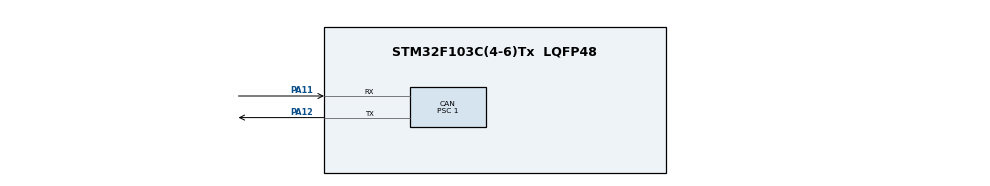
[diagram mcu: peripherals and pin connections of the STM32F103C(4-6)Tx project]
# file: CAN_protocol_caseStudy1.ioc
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CAN.BS1=CAN_BS1_6TQ
CAN.CalculateTimeBit=1000
CAN.CalculateTimeQuantum=125.0
CAN.Mode=CAN_MODE_LOOPBACK
CAN.Prescaler=1
Mcu.Family=STM32F1
Mcu.Name=STM32F103C(4-6)Tx
Mcu.Package=LQFP48
NVIC.PriorityGroup=NVIC_PRIORITYGROUP_4
PA11.Mode=Master
PA11.Signal=CAN_RX
PA12.Mode=Master
PA12.Signal=CAN_TX
ProjectManager.HeapSize=0x200
ProjectManager.StackSize=0x400
ProjectManager.TargetToolchain=STM32CubeIDE
RCC.APB1Freq_Value=8000000
RCC.APB2Freq_Value=8000000
VP_SYS_VS_ND.Mode=No_Debug
board=custom

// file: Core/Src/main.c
/* USER CODE BEGIN Header */
/**
 ******************************************************************************
 * @file           : main.c
 * @brief          : Main program body
 ******************************************************************************
 * @attention
 *
 * <h2><center>&copy; Copyright (c) 2023 STMicroelectronics.
 * All rights reserved.</center></h2>
 *
 * This software component is licensed by ST under BSD 3-Clause license,
 * the "License"; You may not use this file except in compliance with the
 * License. You may obtain a copy of the License at:
 *                        opensource.org/licenses/BSD-3-Clause
 *
 ******************************************************************************
 */
/* USER CODE END Header */
#include "main.h"

CAN_HandleTypeDef hcan;

void SystemClock_Config(void);
static void MX_GPIO_Init(void);
static void MX_CAN_Init(void);

// function to transmit with standard ID
// data frame

void CAN_tx(uint32_t ID, uint32_t DLC, uint8_t *p_payload){

	//	  (#) To manage messages transmission, the following Tx control functions
	//	          can be used:
	//	            (++) HAL_CAN_AddTxMessage() to request transmission of a new
	//	                 message.
	//	            (++) HAL_CAN_AbortTxRequest() to abort transmission of a pending
	//	                 message.
	//	            (++) HAL_CAN_GetTxMailboxesFreeLevel() to get the number of free Tx
	//	                 mailboxes.
	//	            (++) HAL_CAN_IsTxMessagePending() to check if a message is pending
	//	                 in a Tx mailbox.
	//	            (++) HAL_CAN_GetTxTimestamp() to get the timestamp of Tx message
	//	                 sent, if time triggered communication mode is enabled.
	uint32_t TxMailbox;
	CAN_TxHeaderTypeDef pheader;
	if(HAL_CAN_GetTxMailboxesFreeLevel(&hcan)){

		pheader.DLC = DLC;
		pheader.IDE = CAN_ID_STD;
		pheader.RTR = CAN_RTR_DATA;
		pheader.StdId = ID;
		if(HAL_CAN_AddTxMessage(&hcan, &pheader , p_payload,  &TxMailbox) != HAL_OK){
			Error_Handler();
		}
	}
	while (HAL_CAN_IsTxMessagePending(&hcan, TxMailbox));    // wait till frame is done transmitting
}

void CAN_rx_FilterConfig(uint16_t stdID, uint16_t stdMASK){

	CAN_FilterTypeDef filterConfig;
	filterConfig.FilterActivation = CAN_FILTER_ENABLE;
	filterConfig.FilterBank = 0;
	filterConfig.FilterFIFOAssignment = CAN_FILTER_FIFO0;
	filterConfig.FilterIdHigh = stdID << 5;
	filterConfig.FilterMaskIdHigh = stdMASK << 5;
	filterConfig.FilterIdLow = 0x0000;
	filterConfig.FilterMaskIdLow = 0x0000;
	filterConfig.FilterMode = CAN_FILTERMODE_IDMASK;
	filterConfig.FilterScale = CAN_FILTERSCALE_32BIT;

	/**
	 * @brief  Configures the CAN reception filter according to the specified
	 *         parameters in the CAN_FilterInitStruct.
	 * @param  hcan pointer to a CAN_HandleTypeDef structure that contains
	 *         the configuration information for the specified CAN.
	 * @param  sFilterConfig pointer to a CAN_FilterTypeDef structure that
	 *         contains the filter configuration information.
	 * @retval None
	 **/

	if(HAL_CAN_ConfigFilter(&hcan, &filterConfig) != HAL_OK){
		Error_Handler();
	}
}

void CAN_rx(uint32_t *ID, uint8_t *DLC, uint8_t *p_payload){

	//    *** Polling mode operation ***
	//    ==============================
	//  [..]
	//    (#) Reception:
	//          (++) Monitor reception of message using HAL_CAN_GetRxFifoFillLevel()
	//               until at least one message is received.
	//          (++) Then get the message using HAL_CAN_GetRxMessage().

	while(HAL_CAN_GetRxFifoFillLevel(&hcan, CAN_RX_FIFO0) == 0);
	CAN_RxHeaderTypeDef pHeader;
	if(HAL_CAN_GetRxMessage(&hcan, CAN_RX_FIFO0, &pHeader, p_payload) != HAL_OK){
		Error_Handler();
	}
	*DLC = pHeader.DLC;
	*ID = pHeader.StdId;
}

int main(void)
{

	/* MCU Configuration--------------------------------------------------------*/

	/* Reset of all peripherals, Initializes the Flash interface and the Systick. */
	HAL_Init();

	/* Configure the system clock */
	SystemClock_Config();

	/* Initialize all configured peripherals */
	MX_GPIO_Init();
	MX_CAN_Init();

	// Start the bxCAN to start transmitting
	if(HAL_CAN_Start(&hcan) != (HAL_OK)){
		Error_Handler();
	}

	// configure the filter
	CAN_rx_FilterConfig(0x3FF, 0x7FF);

	/* Infinite loop */
	/* USER CODE BEGIN WHILE */

	unsigned char tx_Data[8] = {'C', 'A', 'N', ' ', 'N', 'O', ':', ' '};
	uint8_t frameno = 0;
	unsigned char rx_Data[8];
	uint32_t rx_ID;
	uint8_t rx_DLC;
	while (1)
	{
		/* USER CODE END WHILE */
		tx_Data[7] = frameno++;
		CAN_tx(0x3FF, 8, tx_Data);

		CAN_rx(&rx_ID, &rx_DLC, rx_Data);

	}
}

void SystemClock_Config(void)
{
	RCC_OscInitTypeDef RCC_OscInitStruct = {0};
	RCC_ClkInitTypeDef RCC_ClkInitStruct = {0};

	/** Initializes the RCC Oscillators according to the specified parameters
	 * in the RCC_OscInitTypeDef structure.
	 */
	RCC_OscInitStruct.OscillatorType = RCC_OSCILLATORTYPE_HSI;
	RCC_OscInitStruct.HSIState = RCC_HSI_ON;
	RCC_OscInitStruct.HSICalibrationValue = RCC_HSICALIBRATION_DEFAULT;
	RCC_OscInitStruct.PLL.PLLState = RCC_PLL_NONE;
	if (HAL_RCC_OscConfig(&RCC_OscInitStruct) != HAL_OK)
	{
		Error_Handler();
	}
	/** Initializes the CPU, AHB and APB buses clocks
	 */
	RCC_ClkInitStruct.ClockType = RCC_CLOCKTYPE_HCLK|RCC_CLOCKTYPE_SYSCLK
			|RCC_CLOCKTYPE_PCLK1|RCC_CLOCKTYPE_PCLK2;
	RCC_ClkInitStruct.SYSCLKSource = RCC_SYSCLKSOURCE_HSI;
	RCC_ClkInitStruct.AHBCLKDivider = RCC_SYSCLK_DIV1;
	RCC_ClkInitStruct.APB1CLKDivider = RCC_HCLK_DIV1;
	RCC_ClkInitStruct.APB2CLKDivider = RCC_HCLK_DIV1;

	if (HAL_RCC_ClockConfig(&RCC_ClkInitStruct, FLASH_LATENCY_0) != HAL_OK)
	{
		Error_Handler();
	}
}

static void MX_CAN_Init(void)
{

	hcan.Instance = CAN1;
	hcan.Init.Prescaler = 1;
	hcan.Init.Mode = CAN_MODE_LOOPBACK;
	hcan.Init.SyncJumpWidth = CAN_SJW_1TQ;
	hcan.Init.TimeSeg1 = CAN_BS1_6TQ;
	hcan.Init.TimeSeg2 = CAN_BS2_1TQ;
	hcan.Init.TimeTriggeredMode = DISABLE;
	hcan.Init.AutoBusOff = DISABLE;
	hcan.Init.AutoWakeUp = DISABLE;
	hcan.Init.AutoRetransmission = ENABLE;
	hcan.Init.ReceiveFifoLocked = DISABLE;
	hcan.Init.TransmitFifoPriority = DISABLE;
	if (HAL_CAN_Init(&hcan) != HAL_OK)
	{
		Error_Handler();
	}

}

static void MX_GPIO_Init(void)
{

	/* GPIO Ports Clock Enable */
	__HAL_RCC_GPIOA_CLK_ENABLE();

}

void Error_Handler(void)
{
}

/************************ (C) COPYRIGHT STMicroelectronics *****END OF FILE****/
